# ESP32-C6 register map
Vendor: ESPRESSIF SYSTEMS (SHANGHAI) CO., LTD.; Series: ESP32 C-Series; File version: 12
CPU: RV32IMAC r0p0, little endian, no MPU, no FPU, 0 interrupt priority bits
Address unit: 32 bits
Registers are 32-bit, read-write, reset 0x0 unless marked. A register's access mark holds for its fields unless they carry their own. Offsets are from the block's base; [hi:lo] are bit positions; {n}, {i} and the like mark numbered series.

## LP_PERI — LP_PERI Peripheral
Base 0x600B2800
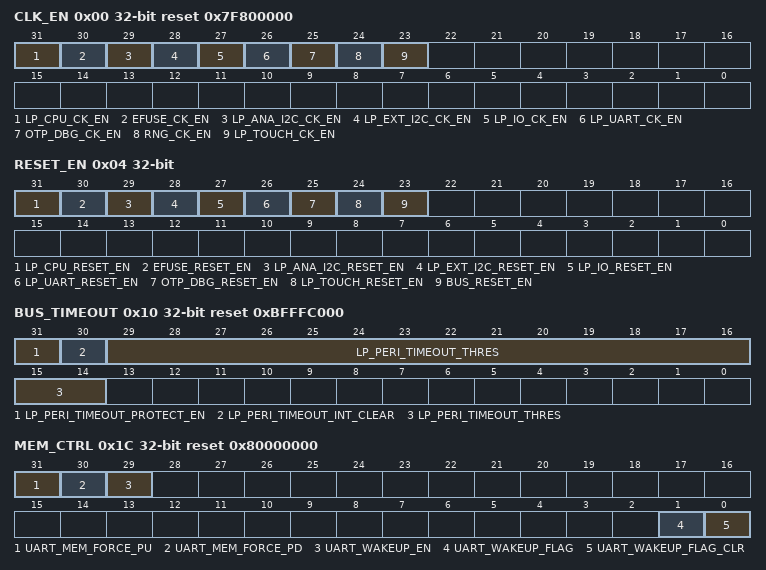
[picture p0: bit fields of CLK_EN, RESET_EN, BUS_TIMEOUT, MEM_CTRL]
0x00 CLK_EN reset 0x7F800000 — need_des
  [31] LP_CPU_CK_EN — need_des
  [30] EFUSE_CK_EN — need_des
  [29] LP_ANA_I2C_CK_EN — need_des
  [28] LP_EXT_I2C_CK_EN — need_des
  [27] LP_IO_CK_EN — need_des
  [26] LP_UART_CK_EN — need_des
  [25] OTP_DBG_CK_EN — need_des
  [24] RNG_CK_EN — need_des
  [23] LP_TOUCH_CK_EN — need_des
0x04 RESET_EN access per field — need_des
  [31] LP_CPU_RESET_EN wo — need_des
  [30] EFUSE_RESET_EN rw — need_des
  [29] LP_ANA_I2C_RESET_EN rw — need_des
  [28] LP_EXT_I2C_RESET_EN rw — need_des
  [27] LP_IO_RESET_EN rw — need_des
  [26] LP_UART_RESET_EN rw — need_des
  [25] OTP_DBG_RESET_EN rw — need_des
  [24] LP_TOUCH_RESET_EN rw — need_des
  [23] BUS_RESET_EN wo — need_des
0x08 RNG_DATA ro — need_des
  [31:0] RND_DATA
0x0C CPU reset 0x80000000 — need_des
  [31] LPCORE_DBGM_UNAVALIABLE
0x10 BUS_TIMEOUT access per field reset 0xBFFFC000 — need_des
  [31] LP_PERI_TIMEOUT_PROTECT_EN rw — need_des
  [30] LP_PERI_TIMEOUT_INT_CLEAR wo — need_des
  [29:14] LP_PERI_TIMEOUT_THRES rw — need_des
0x14 BUS_TIMEOUT_ADDR ro — need_des
  [31:0] LP_PERI_TIMEOUT_ADDR
0x18 BUS_TIMEOUT_UID ro — need_des
  [6:0] LP_PERI_TIMEOUT_UID
0x1C MEM_CTRL access per field reset 0x80000000 — need_des
  [31] UART_MEM_FORCE_PU rw — need_des
  [30] UART_MEM_FORCE_PD rw — need_des
  [29] UART_WAKEUP_EN rw — need_des
  [1] UART_WAKEUP_FLAG rw — need_des
  [0] UART_WAKEUP_FLAG_CLR wo — need_des
0x20 INTERRUPT_SOURCE ro — need_des
  [5:0] LP_INTERRUPT_SOURCE — BIT5~BIT0: pmu_lp_int, modem_lp_int, lp_timer_lp_int, lp_uart_int, lp_i2c_int, lp_io_int
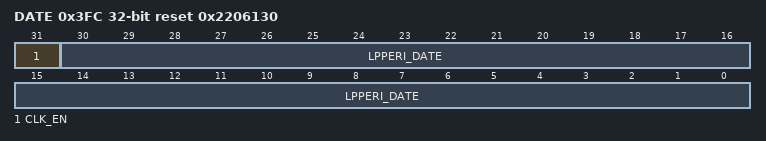
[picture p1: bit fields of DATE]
0x3FC DATE reset 0x2206130 — need_des
  [31] CLK_EN — need_des
  [30:0] LPPERI_DATE — need_des

## LP_ANA — LP_ANA Peripheral
Base 0x600B2C00
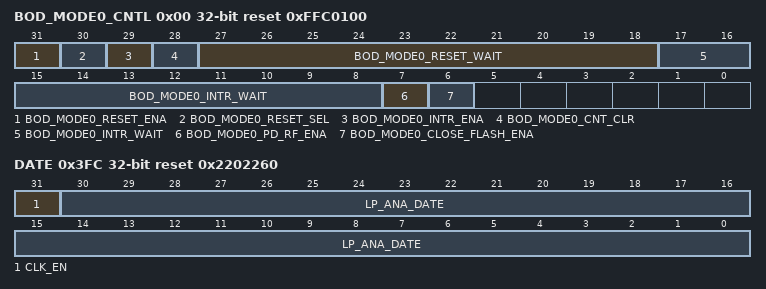
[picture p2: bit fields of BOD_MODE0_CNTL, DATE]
0x00 BOD_MODE0_CNTL reset 0xFFC0100 — need_des
  [31] BOD_MODE0_RESET_ENA — need_des
  [30] BOD_MODE0_RESET_SEL — need_des
  [29] BOD_MODE0_INTR_ENA — need_des
  [28] BOD_MODE0_CNT_CLR — need_des
  [27:18] BOD_MODE0_RESET_WAIT — need_des
  [17:8] BOD_MODE0_INTR_WAIT — need_des
  [7] BOD_MODE0_PD_RF_ENA — need_des
  [6] BOD_MODE0_CLOSE_FLASH_ENA — need_des
0x04 BOD_MODE1_CNTL — need_des
  [31] BOD_MODE1_RESET_ENA
0x08 CK_GLITCH_CNTL — need_des
  [31] CK_GLITCH_RESET_ENA
0x0C FIB_ENABLE reset 0xFFFFFFFF — need_des
  [31:0] ANA_FIB_ENA
0x10 INT_RAW — need_des
  [31] BOD_MODE0_INT_RAW
0x14 INT_ST ro — need_des
  [31] BOD_MODE0_INT_ST
0x18 INT_ENA — need_des
  [31] BOD_MODE0_INT_ENA
0x1C INT_CLR wo — need_des
  [31] BOD_MODE0_INT_CLR
0x20 LP_INT_RAW — need_des
  [31] BOD_MODE0_LP_INT_RAW
0x24 LP_INT_ST ro — need_des
  [31] BOD_MODE0_LP_INT_ST
0x28 LP_INT_ENA — need_des
  [31] BOD_MODE0_LP_INT_ENA
0x2C LP_INT_CLR wo — need_des
  [31] BOD_MODE0_LP_INT_CLR
0x3FC DATE reset 0x2202260 — need_des
  [31] CLK_EN — need_des
  [30:0] LP_ANA_DATE — need_des

## LP_AON — LP_AON Peripheral
Base 0x600B1000
{0x0+4i} STORE{i} (i=0..9) — need_des
  [31:0] LP_AON_STORE{i}
0x28 GPIO_MUX — need_des
  [7:0] SEL
0x2C GPIO_HOLD0 — need_des
0x30 GPIO_HOLD1 — need_des
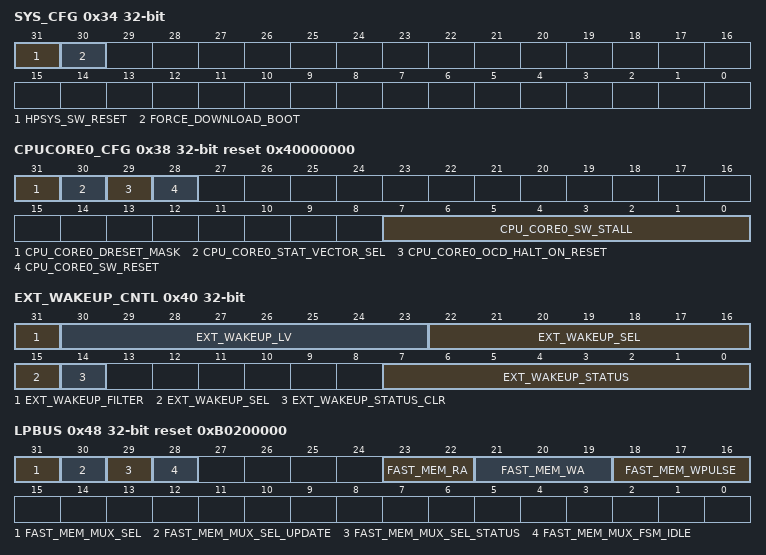
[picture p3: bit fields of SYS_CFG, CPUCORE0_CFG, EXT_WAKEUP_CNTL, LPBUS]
0x34 SYS_CFG access per field — need_des
  [31] HPSYS_SW_RESET wo — need_des
  [30] FORCE_DOWNLOAD_BOOT rw — need_des
0x38 CPUCORE0_CFG access per field reset 0x40000000 — need_des
  [31] CPU_CORE0_DRESET_MASK rw — need_des
  [30] CPU_CORE0_STAT_VECTOR_SEL rw — need_des
  [29] CPU_CORE0_OCD_HALT_ON_RESET rw — need_des
  [28] CPU_CORE0_SW_RESET wo — need_des
  [7:0] CPU_CORE0_SW_STALL rw — need_des
0x3C IO_MUX — need_des
  [31] RESET_DISABLE
0x40 EXT_WAKEUP_CNTL access per field — need_des
  [31] EXT_WAKEUP_FILTER rw — need_des
  [30:23] EXT_WAKEUP_LV rw — need_des
  [22:15] EXT_WAKEUP_SEL rw — need_des
  [14] EXT_WAKEUP_STATUS_CLR wo — need_des
  [7:0] EXT_WAKEUP_STATUS ro — need_des
0x44 USB — need_des
  [31] RESET_DISABLE
0x48 LPBUS access per field reset 0xB0200000 — need_des
  [31] FAST_MEM_MUX_SEL rw — need_des
  [30] FAST_MEM_MUX_SEL_UPDATE wo — need_des
  [29] FAST_MEM_MUX_SEL_STATUS ro — need_des
  [28] FAST_MEM_MUX_FSM_IDLE ro — need_des
  [23:22] FAST_MEM_RA rw — This field controls fast memory RA parameter.
  [21:19] FAST_MEM_WA rw — This field controls fast memory WA parameter.
  [18:16] FAST_MEM_WPULSE rw — This field controls fast memory WPULSE parameter.
0x4C SDIO_ACTIVE reset 0x2800000 — need_des
  [31:22] SDIO_ACT_DNUM
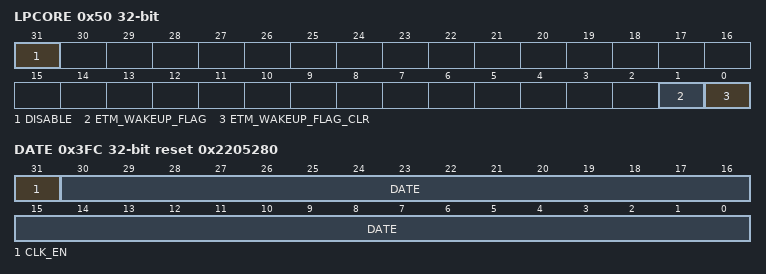
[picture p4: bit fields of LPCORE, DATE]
0x50 LPCORE access per field — need_des
  [31] DISABLE rw — need_des
  [1] ETM_WAKEUP_FLAG rw — need_des
  [0] ETM_WAKEUP_FLAG_CLR wo — need_des
0x54 SAR_CCT — need_des
  [31:29] SAR2_PWDET_CCT
0x3FC DATE reset 0x2205280 — need_des
  [31] CLK_EN — need_des
  [30:0] DATE — need_des
